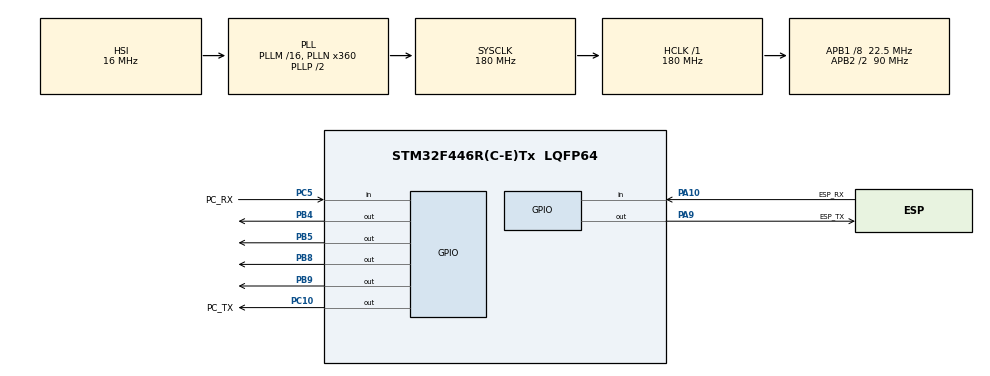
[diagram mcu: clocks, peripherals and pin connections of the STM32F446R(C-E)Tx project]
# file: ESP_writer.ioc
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Mcu.Family=STM32F4
Mcu.Name=STM32F446R(C-E)Tx
Mcu.Package=LQFP64
NVIC.PriorityGroup=NVIC_PRIORITYGROUP_4
PA10.GPIO_Label=ESP_RX
PA10.GPIO_PuPd=GPIO_PULLUP
PA10.Signal=GPIO_Input
PA13.Mode=Serial_Wire
PA13.Signal=SYS_JTMS-SWDIO
PA14.Mode=Serial_Wire
PA14.Signal=SYS_JTCK-SWCLK
PA9.GPIO_Label=ESP_TX
PA9.GPIO_Speed=GPIO_SPEED_FREQ_VERY_HIGH
PA9.Signal=GPIO_Output
PB4.Signal=GPIO_Output
PB5.Signal=GPIO_Output
PB8.Signal=GPIO_Output
PB9.Signal=GPIO_Output
PC10.GPIO_Label=PC_TX
PC10.GPIO_Speed=GPIO_SPEED_FREQ_VERY_HIGH
PC10.Signal=GPIO_Output
PC5.GPIO_Label=PC_RX
PC5.GPIO_PuPd=GPIO_PULLUP
PC5.Signal=GPIO_Input
ProjectManager.HeapSize=0x200
ProjectManager.StackSize=0x400
ProjectManager.TargetToolchain=TrueSTUDIO
RCC.AHBFreq_Value=180000000
RCC.APB1CLKDivider=RCC_HCLK_DIV8
RCC.APB1Freq_Value=22500000
RCC.APB1TimFreq_Value=45000000
RCC.APB2CLKDivider=RCC_HCLK_DIV2
RCC.APB2Freq_Value=90000000
RCC.APB2TimFreq_Value=180000000
RCC.CortexFreq_Value=180000000
RCC.HCLKFreq_Value=180000000
RCC.PLLN=360
RCC.PLLQ=15
RCC.PLLSAIN=180
RCC.SYSCLKFreq_VALUE=180000000
RCC.SYSCLKSource=RCC_SYSCLKSOURCE_PLLCLK
RCC.USBFreq_Value=24000000
RCC.VCOOutputFreq_Value=360000000
board=EDAMAME

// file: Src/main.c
/* USER CODE BEGIN Header */
/**
  ******************************************************************************
  * @file           : main.c
  * @brief          : Main program body
  ******************************************************************************
  * @attention
  *
  * <h2><center>&copy; Copyright (c) 2019 STMicroelectronics.
  * All rights reserved.</center></h2>
  *
  * This software component is licensed by ST under BSD 3-Clause license,
  * the "License"; You may not use this file except in compliance with the
  * License. You may obtain a copy of the License at:
  *                        opensource.org/licenses/BSD-3-Clause
  *
  ******************************************************************************
  */
/* USER CODE END Header */

#include "main.h"

void SystemClock_Config(void);
static void MX_GPIO_Init(void);

int main(void)
{

  /* MCU Configuration--------------------------------------------------------*/

  /* Reset of all peripherals, Initializes the Flash interface and the Systick. */
  HAL_Init();

  /* Configure the system clock */
  SystemClock_Config();

  /* Initialize all configured peripherals */
  MX_GPIO_Init();

  /* Infinite loop */
  while (1)
  {

    /* USER CODE BEGIN 3 */
	  HAL_GPIO_WritePin(PC_TX_GPIO_Port, PC_TX_Pin, HAL_GPIO_ReadPin(ESP_RX_GPIO_Port, ESP_RX_Pin));
	  HAL_GPIO_WritePin(ESP_TX_GPIO_Port, ESP_TX_Pin, HAL_GPIO_ReadPin(PC_RX_GPIO_Port, PC_RX_Pin));
  }
  /* USER CODE END 3 */
}

void SystemClock_Config(void)
{
  RCC_OscInitTypeDef RCC_OscInitStruct = {0};
  RCC_ClkInitTypeDef RCC_ClkInitStruct = {0};

  /** Configure the main internal regulator output voltage
  */
  __HAL_RCC_PWR_CLK_ENABLE();
  __HAL_PWR_VOLTAGESCALING_CONFIG(PWR_REGULATOR_VOLTAGE_SCALE1);
  /** Initializes the CPU, AHB and APB busses clocks
  */
  RCC_OscInitStruct.OscillatorType = RCC_OSCILLATORTYPE_HSI;
  RCC_OscInitStruct.HSIState = RCC_HSI_ON;
  RCC_OscInitStruct.HSICalibrationValue = RCC_HSICALIBRATION_DEFAULT;
  RCC_OscInitStruct.PLL.PLLState = RCC_PLL_ON;
  RCC_OscInitStruct.PLL.PLLSource = RCC_PLLSOURCE_HSI;
  RCC_OscInitStruct.PLL.PLLM = 16;
  RCC_OscInitStruct.PLL.PLLN = 360;
  RCC_OscInitStruct.PLL.PLLP = RCC_PLLP_DIV2;
  RCC_OscInitStruct.PLL.PLLQ = 15;
  RCC_OscInitStruct.PLL.PLLR = 2;
  if (HAL_RCC_OscConfig(&RCC_OscInitStruct) != HAL_OK)
  {
    Error_Handler();
  }
  /** Activate the Over-Drive mode
  */
  if (HAL_PWREx_EnableOverDrive() != HAL_OK)
  {
    Error_Handler();
  }
  /** Initializes the CPU, AHB and APB busses clocks
  */
  RCC_ClkInitStruct.ClockType = RCC_CLOCKTYPE_HCLK|RCC_CLOCKTYPE_SYSCLK
                              |RCC_CLOCKTYPE_PCLK1|RCC_CLOCKTYPE_PCLK2;
  RCC_ClkInitStruct.SYSCLKSource = RCC_SYSCLKSOURCE_PLLCLK;
  RCC_ClkInitStruct.AHBCLKDivider = RCC_SYSCLK_DIV1;
  RCC_ClkInitStruct.APB1CLKDivider = RCC_HCLK_DIV8;
  RCC_ClkInitStruct.APB2CLKDivider = RCC_HCLK_DIV2;

  if (HAL_RCC_ClockConfig(&RCC_ClkInitStruct, FLASH_LATENCY_5) != HAL_OK)
  {
    Error_Handler();
  }
}

static void MX_GPIO_Init(void)
{
  GPIO_InitTypeDef GPIO_InitStruct = {0};

  /* GPIO Ports Clock Enable */
  __HAL_RCC_GPIOC_CLK_ENABLE();
  __HAL_RCC_GPIOA_CLK_ENABLE();
  __HAL_RCC_GPIOB_CLK_ENABLE();

  /*Configure GPIO pin Output Level */
  HAL_GPIO_WritePin(ESP_TX_GPIO_Port, ESP_TX_Pin, GPIO_PIN_RESET);

  /*Configure GPIO pin Output Level */
  HAL_GPIO_WritePin(PC_TX_GPIO_Port, PC_TX_Pin, GPIO_PIN_RESET);

  /*Configure GPIO pin Output Level */
  HAL_GPIO_WritePin(GPIOB, GPIO_PIN_4|GPIO_PIN_5|GPIO_PIN_8|GPIO_PIN_9, GPIO_PIN_RESET);

  /*Configure GPIO pin : PC_RX_Pin */
  GPIO_InitStruct.Pin = PC_RX_Pin;
  GPIO_InitStruct.Mode = GPIO_MODE_INPUT;
  GPIO_InitStruct.Pull = GPIO_PULLUP;
  HAL_GPIO_Init(PC_RX_GPIO_Port, &GPIO_InitStruct);

  /*Configure GPIO pin : ESP_TX_Pin */
  GPIO_InitStruct.Pin = ESP_TX_Pin;
  GPIO_InitStruct.Mode = GPIO_MODE_OUTPUT_PP;
  GPIO_InitStruct.Pull = GPIO_NOPULL;
  GPIO_InitStruct.Speed = GPIO_SPEED_FREQ_VERY_HIGH;
  HAL_GPIO_Init(ESP_TX_GPIO_Port, &GPIO_InitStruct);

  /*Configure GPIO pin : ESP_RX_Pin */
  GPIO_InitStruct.Pin = ESP_RX_Pin;
  GPIO_InitStruct.Mode = GPIO_MODE_INPUT;
  GPIO_InitStruct.Pull = GPIO_PULLUP;
  HAL_GPIO_Init(ESP_RX_GPIO_Port, &GPIO_InitStruct);

  /*Configure GPIO pin : PC_TX_Pin */
  GPIO_InitStruct.Pin = PC_TX_Pin;
  GPIO_InitStruct.Mode = GPIO_MODE_OUTPUT_PP;
  GPIO_InitStruct.Pull = GPIO_NOPULL;
  GPIO_InitStruct.Speed = GPIO_SPEED_FREQ_VERY_HIGH;
  HAL_GPIO_Init(PC_TX_GPIO_Port, &GPIO_InitStruct);

  /*Configure GPIO pins : PB4 PB5 PB8 PB9 */
  GPIO_InitStruct.Pin = GPIO_PIN_4|GPIO_PIN_5|GPIO_PIN_8|GPIO_PIN_9;
  GPIO_InitStruct.Mode = GPIO_MODE_OUTPUT_PP;
  GPIO_InitStruct.Pull = GPIO_NOPULL;
  GPIO_InitStruct.Speed = GPIO_SPEED_FREQ_LOW;
  HAL_GPIO_Init(GPIOB, &GPIO_InitStruct);

}

void Error_Handler(void)
{
}

/************************ (C) COPYRIGHT STMicroelectronics *****END OF FILE****/
